# USB1_VBP2AHB_WRAP_CONTROLLER_VBP_USB3_CORE_SUPPRTCAP3 register map
Vendor: Texas Instruments
Peripheral module from a debugger description file (folder am62P).
Registers are 32-bit, read-only, reset 0x0 unless marked. A register's access mark holds for its fields unless they carry their own. Offsets are as the file gives them; lines under a group give offsets from that group; [hi:lo] are bit positions; {n}, {i} and the like mark numbered series; 'fields as' and 'values as' point back to an identical list; <NAME> marks a mode.

## USB1_VBP2AHB_WRAP_CONTROLLER_VBP_USB3_CORE_SUPPRTCAP3
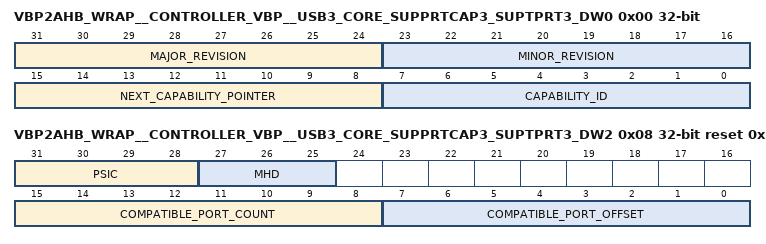
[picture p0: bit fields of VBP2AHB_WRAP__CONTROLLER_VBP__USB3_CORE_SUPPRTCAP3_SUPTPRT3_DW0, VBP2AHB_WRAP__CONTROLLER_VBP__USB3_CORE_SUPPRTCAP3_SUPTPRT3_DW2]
0x00 VBP2AHB_WRAP__CONTROLLER_VBP__USB3_CORE_SUPPRTCAP3_SUPTPRT3_DW0 — Register SUPTPRT3_DW0
  [31:24] MAJOR_REVISION — MAJOR_REVISION For a description of this standard USB register field, see the eXtensible Host Controller Interface for Universal Serial Bus [USB] Specification 3.0.
  [23:16] MINOR_REVISION — MINOR_REVISION For a description of this standard USB register field, see the eXtensible Host Controller Interface for Universal Serial Bus [USB] Specification 3.0.
  [15:8] NEXT_CAPABILITY_POINTER — NEXT_CAPABILITY_POINTER For a description of this standard USB register field, see the eXtensible Host Controller Interface for Universal Serial Bus [USB] Specification 3.0.
  [7:0] CAPABILITY_ID — CAPABILITY_ID For a description of this standard USB register field, see the eXtensible Host Controller Interface for Universal Serial Bus [USB] Specification 3.0.
0x04 VBP2AHB_WRAP__CONTROLLER_VBP__USB3_CORE_SUPPRTCAP3_SUPTPRT3_DW1 — Register SUPTPRT3_DW1
  [31:0] NAME_STRING — NAME_STRING For a description of this standard USB register field, see the eXtensible Host Controller Interface for Universal Serial Bus [USB] Specification 3.0.
0x08 VBP2AHB_WRAP__CONTROLLER_VBP__USB3_CORE_SUPPRTCAP3_SUPTPRT3_DW2 reset 0x102 — SUPTPRT3_DW2 For a description of this standard USB register field, see the eXtensible Host Controller Interface for Universal Serial Bus (USB) Specification 3.0.
  [31:28] PSIC
  [27:25] MHD — Hub Depth For a description of this standard USB register field, see the eXtensible Host Controller Interface for Universal Serial Bus [USB] Specification 3.0.
  [15:8] COMPATIBLE_PORT_COUNT — COMPATIBLE_PORT_COUNT For a description of this standard USB register field, see the eXtensible Host Controller Interface for Universal Serial Bus [USB] Specification 3.0.
  [7:0] COMPATIBLE_PORT_OFFSET — COMPATIBLE_PORT_OFFSET For a description of this standard USB register field, see the eXtensible Host Controller Interface for Universal Serial Bus [USB] Specification 3.0.
0x0C VBP2AHB_WRAP__CONTROLLER_VBP__USB3_CORE_SUPPRTCAP3_SUPTPRT3_DW3 — SUPTPRT3_DW3
  [4:0] PROTCL_SLT_TY — Protocol Slot Type
